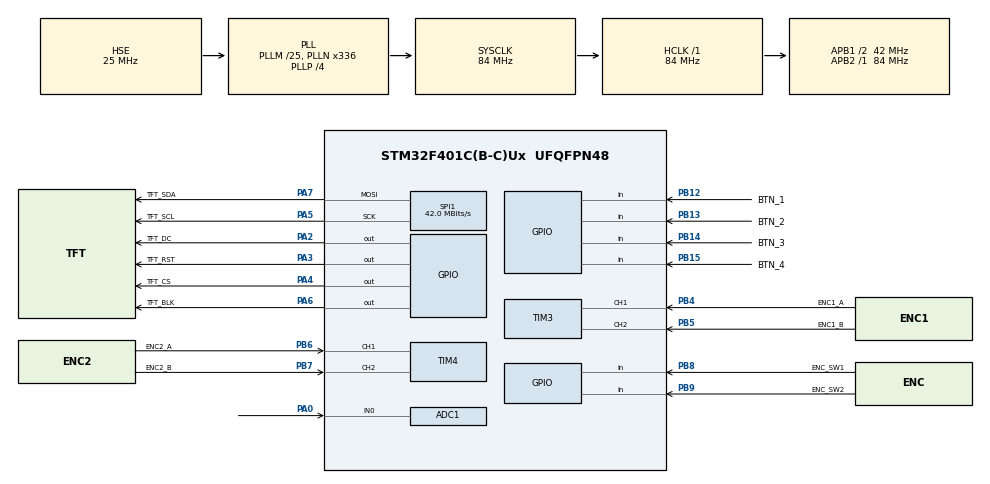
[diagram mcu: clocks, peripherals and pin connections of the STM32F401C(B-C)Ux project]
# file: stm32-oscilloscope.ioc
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ADC1.Channel-0\#ChannelRegularConversion=ADC_CHANNEL_0
ADC1.ExternalTrigConv=ADC_EXTERNALTRIGCONV_T2_TRGO
ADC1.NbrOfConversionFlag=1
ADC1.Rank-0\#ChannelRegularConversion=1
ADC1.SamplingTime-0\#ChannelRegularConversion=ADC_SAMPLETIME_15CYCLES
ADC1.master=1
Dma.ADC1.1.Direction=DMA_PERIPH_TO_MEMORY
Dma.ADC1.1.FIFOMode=DMA_FIFOMODE_DISABLE
Dma.ADC1.1.Instance=DMA2_Stream0
Dma.ADC1.1.MemDataAlignment=DMA_MDATAALIGN_HALFWORD
Dma.ADC1.1.MemInc=DMA_MINC_ENABLE
Dma.ADC1.1.Mode=DMA_CIRCULAR
Dma.ADC1.1.PeriphDataAlignment=DMA_PDATAALIGN_HALFWORD
Dma.ADC1.1.PeriphInc=DMA_PINC_DISABLE
Dma.ADC1.1.Priority=DMA_PRIORITY_LOW
Dma.Request0=SPI1_TX
Dma.Request1=ADC1
Dma.SPI1_TX.0.Direction=DMA_MEMORY_TO_PERIPH
Dma.SPI1_TX.0.FIFOMode=DMA_FIFOMODE_DISABLE
Dma.SPI1_TX.0.Instance=DMA2_Stream3
Dma.SPI1_TX.0.MemDataAlignment=DMA_MDATAALIGN_BYTE
Dma.SPI1_TX.0.MemInc=DMA_MINC_ENABLE
Dma.SPI1_TX.0.Mode=DMA_NORMAL
Dma.SPI1_TX.0.PeriphDataAlignment=DMA_PDATAALIGN_BYTE
Dma.SPI1_TX.0.PeriphInc=DMA_PINC_DISABLE
Dma.SPI1_TX.0.Priority=DMA_PRIORITY_LOW
Mcu.Family=STM32F4
Mcu.Name=STM32F401C(B-C)Ux
Mcu.Package=UFQFPN48
NVIC.DMA2_Stream0_IRQn=true\:0\:0\:false\:false\:true\:false\:true\:true
NVIC.DMA2_Stream3_IRQn=true\:0\:0\:false\:false\:true\:false\:true\:true
NVIC.PriorityGroup=NVIC_PRIORITYGROUP_4
PA0-WKUP.Signal=ADCx_IN0
PA13.Mode=Serial_Wire
PA13.Signal=SYS_JTMS-SWDIO
PA14.Mode=Serial_Wire
PA14.Signal=SYS_JTCK-SWCLK
PA2.GPIO_Label=TFT_DC
PA2.Signal=GPIO_Output
PA3.GPIO_Label=TFT_RST
PA3.Signal=GPIO_Output
PA4.GPIO_Label=TFT_CS
PA4.Signal=GPIO_Output
PA5.GPIO_Label=TFT_SCL
PA5.Mode=TX_Only_Simplex_Unidirect_Master
PA5.Signal=SPI1_SCK
PA6.GPIO_Label=TFT_BLK
PA6.Signal=GPIO_Output
PA7.GPIO_Label=TFT_SDA
PA7.Mode=TX_Only_Simplex_Unidirect_Master
PA7.Signal=SPI1_MOSI
PB12.GPIO_Label=BTN_1
PB12.GPIO_PuPd=GPIO_PULLUP
PB12.Signal=GPIO_Input
PB13.GPIO_Label=BTN_2
PB13.GPIO_PuPd=GPIO_PULLUP
PB13.Signal=GPIO_Input
PB14.GPIO_Label=BTN_3
PB14.GPIO_PuPd=GPIO_PULLUP
PB14.Signal=GPIO_Input
PB15.GPIO_Label=BTN_4
PB15.GPIO_PuPd=GPIO_PULLUP
PB15.Signal=GPIO_Input
PB4.GPIO_Label=ENC1_A
PB4.Signal=S_TIM3_CH1
PB5.GPIO_Label=ENC1_B
PB5.Signal=S_TIM3_CH2
PB6.GPIO_Label=ENC2_A
PB6.Signal=S_TIM4_CH1
PB7.GPIO_Label=ENC2_B
PB7.Signal=S_TIM4_CH2
PB8.GPIO_Label=ENC_SW1
PB8.GPIO_PuPd=GPIO_PULLUP
PB8.Signal=GPIO_Input
PB9.GPIO_Label=ENC_SW2
PB9.GPIO_PuPd=GPIO_PULLUP
PB9.Signal=GPIO_Input
PH0\ -\ OSC_IN.Mode=HSE-External-Oscillator
PH0\ -\ OSC_IN.Signal=RCC_OSC_IN
PH1\ -\ OSC_OUT.Mode=HSE-External-Oscillator
PH1\ -\ OSC_OUT.Signal=RCC_OSC_OUT
ProjectManager.HeapSize=0x200
ProjectManager.StackSize=0x400
ProjectManager.TargetToolchain=CMake
RCC.48MHZClocksFreq_Value=84000000
RCC.AHBFreq_Value=84000000
RCC.APB1CLKDivider=RCC_HCLK_DIV2
RCC.APB1Freq_Value=42000000
RCC.APB1TimFreq_Value=84000000
RCC.APB2Freq_Value=84000000
RCC.APB2TimFreq_Value=84000000
RCC.CortexFreq_Value=84000000
RCC.EnbaleCSS=true
RCC.HCLKFreq_Value=84000000
RCC.HSE_VALUE=25000000
RCC.HSI_VALUE=16000000
RCC.LSE_VALUE=32768
RCC.PLLM=25
RCC.PLLN=336
RCC.PLLP=RCC_PLLP_DIV4
RCC.PLLSourceVirtual=RCC_PLLSOURCE_HSE
RCC.SYSCLKFreq_VALUE=84000000
RCC.SYSCLKSource=RCC_SYSCLKSOURCE_PLLCLK
RCC.VCOOutputFreq_Value=336000000
SH.ADCx_IN0.0=ADC1_IN0,IN0
SH.S_TIM3_CH1.0=TIM3_CH1,Encoder_Interface
SH.S_TIM3_CH2.0=TIM3_CH2,Encoder_Interface
SH.S_TIM4_CH1.0=TIM4_CH1,Encoder_Interface
SH.S_TIM4_CH2.0=TIM4_CH2,Encoder_Interface
SPI1.BaudRatePrescaler=SPI_BAUDRATEPRESCALER_2
SPI1.CalculateBaudRate=42.0 MBits/s
SPI1.Direction=SPI_DIRECTION_2LINES
SPI1.Mode=SPI_MODE_MASTER
SPI1.VirtualType=VM_MASTER
TIM2.Period=999
TIM2.Prescaler=83
TIM2.TIM_MasterOutputTrigger=TIM_TRGO_UPDATE
TIM3.EncoderMode=TIM_ENCODERMODE_TI12
TIM3.IC1Filter=15
TIM3.IC2Filter=15
TIM4.EncoderMode=TIM_ENCODERMODE_TI12
TIM4.IC1Filter=15
TIM4.IC2Filter=15
VP_TIM2_VS_ClockSourceINT.Mode=Internal
board=custom

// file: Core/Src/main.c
/* USER CODE BEGIN Header */
/**
  ******************************************************************************
  * @file           : main.c
  * @brief          : Main program body
  ******************************************************************************
  * @attention
  *
  * Copyright (c) 2026 STMicroelectronics.
  * All rights reserved.
  *
  * This software is licensed under terms that can be found in the LICENSE file
  * in the root directory of this software component.
  * If no LICENSE file comes with this software, it is provided AS-IS.
  *
  ******************************************************************************
  */
/* USER CODE END Header */
#include "main.h"

/* USER CODE BEGIN Includes */
#include "app.h"
#include "dwt_timer.h"
/* USER CODE END Includes */

ADC_HandleTypeDef hadc1;
DMA_HandleTypeDef hdma_adc1;

SPI_HandleTypeDef hspi1;
DMA_HandleTypeDef hdma_spi1_tx;

TIM_HandleTypeDef htim2;
TIM_HandleTypeDef htim3;
TIM_HandleTypeDef htim4;

void SystemClock_Config(void);
static void MX_GPIO_Init(void);
static void MX_DMA_Init(void);
static void MX_SPI1_Init(void);
static void MX_ADC1_Init(void);
static void MX_TIM2_Init(void);
static void MX_TIM3_Init(void);
static void MX_TIM4_Init(void);

/* USER CODE BEGIN 0 */
#if APP_ENABLE_UART_LOGS
int __io_putchar(int ch) {
    HAL_UART_Transmit(&huart1, (uint8_t *)&ch, 1, 0xFFFF);
    return ch;
}
#endif
/* USER CODE END 0 */

int main(void)
{

  /* USER CODE BEGIN 1 */
  dwt_reset_timer();
  /* USER CODE END 1 */

  /* MCU Configuration--------------------------------------------------------*/

  /* Reset of all peripherals, Initializes the Flash interface and the Systick. */
  HAL_Init();

  /* Configure the system clock */
  SystemClock_Config();

  /* Initialize all configured peripherals */
  MX_GPIO_Init();
  MX_DMA_Init();
  MX_SPI1_Init();
  MX_ADC1_Init();
  MX_TIM2_Init();
  MX_TIM3_Init();
  MX_TIM4_Init();
  /* USER CODE BEGIN 2 */

  app_start();

  /* USER CODE END 2 */

  /* Infinite loop */
  /* USER CODE BEGIN WHILE */
  // while (1)
  // {
    /* USER CODE END WHILE */

    /* USER CODE BEGIN 3 */
//  }
  /* USER CODE END 3 */
}

void SystemClock_Config(void)
{
  RCC_OscInitTypeDef RCC_OscInitStruct = {0};
  RCC_ClkInitTypeDef RCC_ClkInitStruct = {0};

  /** Configure the main internal regulator output voltage
  */
  __HAL_RCC_PWR_CLK_ENABLE();
  __HAL_PWR_VOLTAGESCALING_CONFIG(PWR_REGULATOR_VOLTAGE_SCALE2);

  /** Initializes the RCC Oscillators according to the specified parameters
  * in the RCC_OscInitTypeDef structure.
  */
  RCC_OscInitStruct.OscillatorType = RCC_OSCILLATORTYPE_HSE;
  RCC_OscInitStruct.HSEState = RCC_HSE_ON;
  RCC_OscInitStruct.PLL.PLLState = RCC_PLL_ON;
  RCC_OscInitStruct.PLL.PLLSource = RCC_PLLSOURCE_HSE;
  RCC_OscInitStruct.PLL.PLLM = 25;
  RCC_OscInitStruct.PLL.PLLN = 336;
  RCC_OscInitStruct.PLL.PLLP = RCC_PLLP_DIV4;
  RCC_OscInitStruct.PLL.PLLQ = 4;
  if (HAL_RCC_OscConfig(&RCC_OscInitStruct) != HAL_OK)
  {
    Error_Handler();
  }

  /** Initializes the CPU, AHB and APB buses clocks
  */
  RCC_ClkInitStruct.ClockType = RCC_CLOCKTYPE_HCLK|RCC_CLOCKTYPE_SYSCLK
                              |RCC_CLOCKTYPE_PCLK1|RCC_CLOCKTYPE_PCLK2;
  RCC_ClkInitStruct.SYSCLKSource = RCC_SYSCLKSOURCE_PLLCLK;
  RCC_ClkInitStruct.AHBCLKDivider = RCC_SYSCLK_DIV1;
  RCC_ClkInitStruct.APB1CLKDivider = RCC_HCLK_DIV2;
  RCC_ClkInitStruct.APB2CLKDivider = RCC_HCLK_DIV1;

  if (HAL_RCC_ClockConfig(&RCC_ClkInitStruct, FLASH_LATENCY_2) != HAL_OK)
  {
    Error_Handler();
  }

  /** Enables the Clock Security System
  */
  HAL_RCC_EnableCSS();
}

static void MX_ADC1_Init(void)
{

  ADC_ChannelConfTypeDef sConfig = {0};

  /** Configure the global features of the ADC (Clock, Resolution, Data Alignment and number of conversion)
  */
  hadc1.Instance = ADC1;
  hadc1.Init.ClockPrescaler = ADC_CLOCK_SYNC_PCLK_DIV4;
  hadc1.Init.Resolution = ADC_RESOLUTION_12B;
  hadc1.Init.ScanConvMode = DISABLE;
  hadc1.Init.ContinuousConvMode = DISABLE;
  hadc1.Init.DiscontinuousConvMode = DISABLE;
  hadc1.Init.ExternalTrigConvEdge = ADC_EXTERNALTRIGCONVEDGE_RISING;
  hadc1.Init.ExternalTrigConv = ADC_EXTERNALTRIGCONV_T2_TRGO;
  hadc1.Init.DataAlign = ADC_DATAALIGN_RIGHT;
  hadc1.Init.NbrOfConversion = 1;
  hadc1.Init.DMAContinuousRequests = DISABLE;
  hadc1.Init.EOCSelection = ADC_EOC_SINGLE_CONV;
  if (HAL_ADC_Init(&hadc1) != HAL_OK)
  {
    Error_Handler();
  }

  /** Configure for the selected ADC regular channel its corresponding rank in the sequencer and its sample time.
  */
  sConfig.Channel = ADC_CHANNEL_0;
  sConfig.Rank = 1;
  sConfig.SamplingTime = ADC_SAMPLETIME_15CYCLES;
  if (HAL_ADC_ConfigChannel(&hadc1, &sConfig) != HAL_OK)
  {
    Error_Handler();
  }

}

static void MX_SPI1_Init(void)
{

  /* SPI1 parameter configuration*/
  hspi1.Instance = SPI1;
  hspi1.Init.Mode = SPI_MODE_MASTER;
  hspi1.Init.Direction = SPI_DIRECTION_2LINES;
  hspi1.Init.DataSize = SPI_DATASIZE_8BIT;
  hspi1.Init.CLKPolarity = SPI_POLARITY_LOW;
  hspi1.Init.CLKPhase = SPI_PHASE_1EDGE;
  hspi1.Init.NSS = SPI_NSS_SOFT;
  hspi1.Init.BaudRatePrescaler = SPI_BAUDRATEPRESCALER_2;
  hspi1.Init.FirstBit = SPI_FIRSTBIT_MSB;
  hspi1.Init.TIMode = SPI_TIMODE_DISABLE;
  hspi1.Init.CRCCalculation = SPI_CRCCALCULATION_DISABLE;
  hspi1.Init.CRCPolynomial = 10;
  if (HAL_SPI_Init(&hspi1) != HAL_OK)
  {
    Error_Handler();
  }

}

static void MX_TIM2_Init(void)
{

  TIM_ClockConfigTypeDef sClockSourceConfig = {0};
  TIM_MasterConfigTypeDef sMasterConfig = {0};

  htim2.Instance = TIM2;
  htim2.Init.Prescaler = 83;
  htim2.Init.CounterMode = TIM_COUNTERMODE_UP;
  htim2.Init.Period = 999;
  htim2.Init.ClockDivision = TIM_CLOCKDIVISION_DIV1;
  htim2.Init.AutoReloadPreload = TIM_AUTORELOAD_PRELOAD_DISABLE;
  if (HAL_TIM_Base_Init(&htim2) != HAL_OK)
  {
    Error_Handler();
  }
  sClockSourceConfig.ClockSource = TIM_CLOCKSOURCE_INTERNAL;
  if (HAL_TIM_ConfigClockSource(&htim2, &sClockSourceConfig) != HAL_OK)
  {
    Error_Handler();
  }
  sMasterConfig.MasterOutputTrigger = TIM_TRGO_UPDATE;
  sMasterConfig.MasterSlaveMode = TIM_MASTERSLAVEMODE_DISABLE;
  if (HAL_TIMEx_MasterConfigSynchronization(&htim2, &sMasterConfig) != HAL_OK)
  {
    Error_Handler();
  }

}

static void MX_TIM3_Init(void)
{

  TIM_Encoder_InitTypeDef sConfig = {0};
  TIM_MasterConfigTypeDef sMasterConfig = {0};

  htim3.Instance = TIM3;
  htim3.Init.Prescaler = 0;
  htim3.Init.CounterMode = TIM_COUNTERMODE_UP;
  htim3.Init.Period = 65535;
  htim3.Init.ClockDivision = TIM_CLOCKDIVISION_DIV1;
  htim3.Init.AutoReloadPreload = TIM_AUTORELOAD_PRELOAD_DISABLE;
  sConfig.EncoderMode = TIM_ENCODERMODE_TI12;
  sConfig.IC1Polarity = TIM_ICPOLARITY_RISING;
  sConfig.IC1Selection = TIM_ICSELECTION_DIRECTTI;
  sConfig.IC1Prescaler = TIM_ICPSC_DIV1;
  sConfig.IC1Filter = 15;
  sConfig.IC2Polarity = TIM_ICPOLARITY_RISING;
  sConfig.IC2Selection = TIM_ICSELECTION_DIRECTTI;
  sConfig.IC2Prescaler = TIM_ICPSC_DIV1;
  sConfig.IC2Filter = 15;
  if (HAL_TIM_Encoder_Init(&htim3, &sConfig) != HAL_OK)
  {
    Error_Handler();
  }
  sMasterConfig.MasterOutputTrigger = TIM_TRGO_RESET;
  sMasterConfig.MasterSlaveMode = TIM_MASTERSLAVEMODE_DISABLE;
  if (HAL_TIMEx_MasterConfigSynchronization(&htim3, &sMasterConfig) != HAL_OK)
  {
    Error_Handler();
  }

}

static void MX_TIM4_Init(void)
{

  TIM_Encoder_InitTypeDef sConfig = {0};
  TIM_MasterConfigTypeDef sMasterConfig = {0};

  htim4.Instance = TIM4;
  htim4.Init.Prescaler = 0;
  htim4.Init.CounterMode = TIM_COUNTERMODE_UP;
  htim4.Init.Period = 65535;
  htim4.Init.ClockDivision = TIM_CLOCKDIVISION_DIV1;
  htim4.Init.AutoReloadPreload = TIM_AUTORELOAD_PRELOAD_DISABLE;
  sConfig.EncoderMode = TIM_ENCODERMODE_TI12;
  sConfig.IC1Polarity = TIM_ICPOLARITY_RISING;
  sConfig.IC1Selection = TIM_ICSELECTION_DIRECTTI;
  sConfig.IC1Prescaler = TIM_ICPSC_DIV1;
  sConfig.IC1Filter = 15;
  sConfig.IC2Polarity = TIM_ICPOLARITY_RISING;
  sConfig.IC2Selection = TIM_ICSELECTION_DIRECTTI;
  sConfig.IC2Prescaler = TIM_ICPSC_DIV1;
  sConfig.IC2Filter = 15;
  if (HAL_TIM_Encoder_Init(&htim4, &sConfig) != HAL_OK)
  {
    Error_Handler();
  }
  sMasterConfig.MasterOutputTrigger = TIM_TRGO_RESET;
  sMasterConfig.MasterSlaveMode = TIM_MASTERSLAVEMODE_DISABLE;
  if (HAL_TIMEx_MasterConfigSynchronization(&htim4, &sMasterConfig) != HAL_OK)
  {
    Error_Handler();
  }

}

static void MX_DMA_Init(void)
{

  /* DMA controller clock enable */
  __HAL_RCC_DMA2_CLK_ENABLE();

  /* DMA interrupt init */
  /* DMA2_Stream0_IRQn interrupt configuration */
  HAL_NVIC_SetPriority(DMA2_Stream0_IRQn, 0, 0);
  HAL_NVIC_EnableIRQ(DMA2_Stream0_IRQn);
  /* DMA2_Stream3_IRQn interrupt configuration */
  HAL_NVIC_SetPriority(DMA2_Stream3_IRQn, 0, 0);
  HAL_NVIC_EnableIRQ(DMA2_Stream3_IRQn);

}

static void MX_GPIO_Init(void)
{
  GPIO_InitTypeDef GPIO_InitStruct = {0};

  /* GPIO Ports Clock Enable */
  __HAL_RCC_GPIOH_CLK_ENABLE();
  __HAL_RCC_GPIOA_CLK_ENABLE();
  __HAL_RCC_GPIOB_CLK_ENABLE();

  /*Configure GPIO pin Output Level */
  HAL_GPIO_WritePin(GPIOA, TFT_DC_Pin|TFT_RST_Pin|TFT_CS_Pin|TFT_BLK_Pin, GPIO_PIN_RESET);

  /*Configure GPIO pins : TFT_DC_Pin TFT_RST_Pin TFT_CS_Pin TFT_BLK_Pin */
  GPIO_InitStruct.Pin = TFT_DC_Pin|TFT_RST_Pin|TFT_CS_Pin|TFT_BLK_Pin;
  GPIO_InitStruct.Mode = GPIO_MODE_OUTPUT_PP;
  GPIO_InitStruct.Pull = GPIO_NOPULL;
  GPIO_InitStruct.Speed = GPIO_SPEED_FREQ_LOW;
  HAL_GPIO_Init(GPIOA, &GPIO_InitStruct);

  /*Configure GPIO pins : BTN_1_Pin BTN_2_Pin BTN_3_Pin BTN_4_Pin
                           ENC_SW1_Pin ENC_SW2_Pin */
  GPIO_InitStruct.Pin = BTN_1_Pin|BTN_2_Pin|BTN_3_Pin|BTN_4_Pin
                          |ENC_SW1_Pin|ENC_SW2_Pin;
  GPIO_InitStruct.Mode = GPIO_MODE_INPUT;
  GPIO_InitStruct.Pull = GPIO_PULLUP;
  HAL_GPIO_Init(GPIOB, &GPIO_InitStruct);

}

void Error_Handler(void)
{
  __disable_irq();
  while (1)
  {
  }
}
